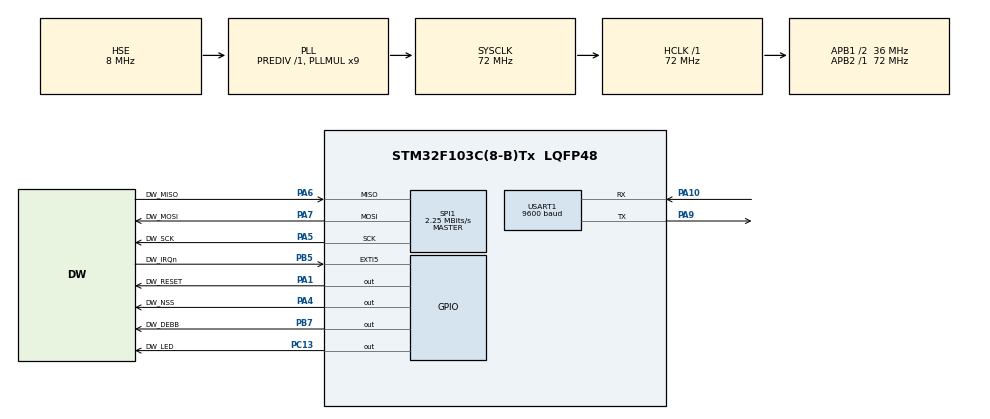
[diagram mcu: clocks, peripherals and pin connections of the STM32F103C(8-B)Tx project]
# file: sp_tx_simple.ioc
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Mcu.Family=STM32F1
Mcu.Name=STM32F103C(8-B)Tx
Mcu.Package=LQFP48
NVIC.EXTI9_5_IRQn=true\:1\:0\:true\:true\:true\:1\:true
NVIC.PriorityGroup=NVIC_PRIORITYGROUP_4
NVIC.TIM2_IRQn=true\:2\:0\:true\:true\:true\:2\:true
NVIC.TIM3_IRQn=true\:3\:0\:true\:true\:true\:3\:true
PA1.GPIO_Label=DW_RESET
PA1.GPIO_ModeDefaultOutputPP=GPIO_MODE_OUTPUT_OD
PA1.GPIO_Speed=GPIO_SPEED_FREQ_HIGH
PA1.PinState=GPIO_PIN_SET
PA1.Signal=GPIO_Output
PA10.Mode=Asynchronous
PA10.Signal=USART1_RX
PA13.Mode=Serial_Wire
PA13.Signal=SYS_JTMS-SWDIO
PA14.Mode=Serial_Wire
PA14.Signal=SYS_JTCK-SWCLK
PA4.GPIO_Label=DW_NSS
PA4.GPIO_Speed=GPIO_SPEED_FREQ_HIGH
PA4.PinState=GPIO_PIN_SET
PA4.Signal=GPIO_Output
PA5.GPIO_Label=DW_SCK
PA5.Mode=Full_Duplex_Master
PA5.Signal=SPI1_SCK
PA6.GPIO_Label=DW_MISO
PA6.Mode=Full_Duplex_Master
PA6.Signal=SPI1_MISO
PA7.GPIO_Label=DW_MOSI
PA7.Mode=Full_Duplex_Master
PA7.Signal=SPI1_MOSI
PA9.Mode=Asynchronous
PA9.Signal=USART1_TX
PB5.GPIO_Label=DW_IRQn
PB5.GPIO_PuPd=GPIO_PULLDOWN
PB5.Signal=GPXTI5
PB7.GPIO_Label=DW_DEBB
PB7.GPIO_Speed=GPIO_SPEED_FREQ_HIGH
PB7.PinState=GPIO_PIN_SET
PB7.Signal=GPIO_Output
PC13-TAMPER-RTC.GPIO_Label=DW_LED
PC13-TAMPER-RTC.GPIO_Speed=GPIO_SPEED_FREQ_HIGH
PC13-TAMPER-RTC.PinState=GPIO_PIN_SET
PC13-TAMPER-RTC.Signal=GPIO_Output
PC14-OSC32_IN.Mode=LSE-External-Oscillator
PC14-OSC32_IN.Signal=RCC_OSC32_IN
PC15-OSC32_OUT.Mode=LSE-External-Oscillator
PC15-OSC32_OUT.Signal=RCC_OSC32_OUT
PD0-OSC_IN.Mode=HSE-External-Oscillator
PD0-OSC_IN.Signal=RCC_OSC_IN
PD1-OSC_OUT.Mode=HSE-External-Oscillator
PD1-OSC_OUT.Signal=RCC_OSC_OUT
ProjectManager.HeapSize=0x1024
ProjectManager.StackSize=0x2048
ProjectManager.TargetToolchain=SW4STM32
RCC.AHBFreq_Value=72000000
RCC.APB1CLKDivider=RCC_HCLK_DIV2
RCC.APB1Freq_Value=36000000
RCC.APB1TimFreq_Value=72000000
RCC.APB2Freq_Value=72000000
RCC.APB2TimFreq_Value=72000000
RCC.HCLKFreq_Value=72000000
RCC.PLLMUL=RCC_PLL_MUL9
RCC.PLLSourceVirtual=RCC_PLLSOURCE_HSE
RCC.RCC_MCOSource=RCC_MCO1SOURCE_HSE
RCC.SYSCLKFreq_VALUE=72000000
RCC.SYSCLKSource=RCC_SYSCLKSOURCE_PLLCLK
RCC.USBFreq_Value=72000000
SPI1.BaudRatePrescaler=SPI_BAUDRATEPRESCALER_32
SPI1.CalculateBaudRate=2.25 MBits/s
SPI1.Direction=SPI_DIRECTION_2LINES
SPI1.Mode=SPI_MODE_MASTER
SPI1.VirtualType=VM_MASTER
TIM2.Period=14
TIM2.Prescaler=35999
TIM3.Period=1999
TIM3.Prescaler=35999
USART1.BaudRate=9600
USART1.VirtualMode=VM_ASYNC
VP_TIM2_VS_ClockSourceINT.Mode=Internal
VP_TIM3_VS_ClockSourceINT.Mode=Internal
board=sp_tx_simple

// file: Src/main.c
/**
  ******************************************************************************
  * File Name          : main.c
  * Description        : Main program body
  ******************************************************************************
  ** This notice applies to any and all portions of this file
  * that are not between comment pairs USER CODE BEGIN and
  * USER CODE END. Other portions of this file, whether
  * inserted by the user or by software development tools
  * are owned by their respective copyright owners.
  *
  * COPYRIGHT(c) 2018 STMicroelectronics
  *
  * Redistribution and use in source and binary forms, with or without modification,
  * are permitted provided that the following conditions are met:
  *   1. Redistributions of source code must retain the above copyright notice,
  *      this list of conditions and the following disclaimer.
  *   2. Redistributions in binary form must reproduce the above copyright notice,
  *      this list of conditions and the following disclaimer in the documentation
  *      and/or other materials provided with the distribution.
  *   3. Neither the name of STMicroelectronics nor the names of its contributors
  *      may be used to endorse or promote products derived from this software
  *      without specific prior written permission.
  *
  * THIS SOFTWARE IS PROVIDED BY THE COPYRIGHT HOLDERS AND CONTRIBUTORS "AS IS"
  * AND ANY EXPRESS OR IMPLIED WARRANTIES, INCLUDING, BUT NOT LIMITED TO, THE
  * IMPLIED WARRANTIES OF MERCHANTABILITY AND FITNESS FOR A PARTICULAR PURPOSE ARE
  * DISCLAIMED. IN NO EVENT SHALL THE COPYRIGHT HOLDER OR CONTRIBUTORS BE LIABLE
  * FOR ANY DIRECT, INDIRECT, INCIDENTAL, SPECIAL, EXEMPLARY, OR CONSEQUENTIAL
  * DAMAGES (INCLUDING, BUT NOT LIMITED TO, PROCUREMENT OF SUBSTITUTE GOODS OR
  * SERVICES; LOSS OF USE, DATA, OR PROFITS; OR BUSINESS INTERRUPTION) HOWEVER
  * CAUSED AND ON ANY THEORY OF LIABILITY, WHETHER IN CONTRACT, STRICT LIABILITY,
  * OR TORT (INCLUDING NEGLIGENCE OR OTHERWISE) ARISING IN ANY WAY OUT OF THE USE
  * OF THIS SOFTWARE, EVEN IF ADVISED OF THE POSSIBILITY OF SUCH DAMAGE.
  *
  ******************************************************************************
  */

#include "main.h"
#include "stm32f1xx_hal.h"

SPI_HandleTypeDef hspi1;

TIM_HandleTypeDef htim2;
TIM_HandleTypeDef htim3;

UART_HandleTypeDef huart1;

/* USER CODE BEGIN PV */
/* Private variables ---------------------------------------------------------*/

/* USER CODE END PV */

void SystemClock_Config(void);
static void MX_GPIO_Init(void);
static void MX_SPI1_Init(void);
static void MX_USART1_UART_Init(void);
static void MX_TIM2_Init(void);
static void MX_TIM3_Init(void);
static void MX_NVIC_Init(void);

/* USER CODE BEGIN PFP */
/* Private function prototypes -----------------------------------------------*/
extern void dw_main(void);
/* USER CODE END PFP */

/* USER CODE BEGIN 0 */
/*
#ifdef __GNUC__
#define PUTCHAR_PROTOTYPE int __io_putchar(int ch)
#else
#define PUTCHAR_PROTOTYPE int fputc(int ch, FILE *f)
#endif  __GNUC__
*/
/* USER CODE END 0 */

int main(void)
{

  /* MCU Configuration----------------------------------------------------------*/

  /* Reset of all peripherals, Initializes the Flash interface and the Systick. */
  HAL_Init();

  /* Configure the system clock */
  SystemClock_Config();

  /* Initialize all configured peripherals */
  MX_GPIO_Init();
  MX_SPI1_Init();
  MX_USART1_UART_Init();
  MX_TIM2_Init();
  MX_TIM3_Init();

  /* Initialize interrupts */
  MX_NVIC_Init();

  /* USER CODE BEGIN 2 */

/*  pitos = __HAL_RCC_TIM2_IS_CLK_ENABLED();
  if (pitos)
	  __HAL_RCC_TIM2_CLK_DISABLE();
  pitos = __HAL_RCC_TIM2_IS_CLK_ENABLED();*/

  __HAL_DBGMCU_FREEZE_TIM2();
  __HAL_DBGMCU_FREEZE_TIM3();

  dw_main();
  /* USER CODE END 2 */

  /* Infinite loop */
  while (1)
  {

  }

}

/** System Clock Configuration
*/
void SystemClock_Config(void)
{

  RCC_OscInitTypeDef RCC_OscInitStruct;
  RCC_ClkInitTypeDef RCC_ClkInitStruct;

    /**Initializes the CPU, AHB and APB busses clocks
    */
  RCC_OscInitStruct.OscillatorType = RCC_OSCILLATORTYPE_HSE;
  RCC_OscInitStruct.HSEState = RCC_HSE_ON;
  RCC_OscInitStruct.HSEPredivValue = RCC_HSE_PREDIV_DIV1;
  RCC_OscInitStruct.HSIState = RCC_HSI_ON;
  RCC_OscInitStruct.PLL.PLLState = RCC_PLL_ON;
  RCC_OscInitStruct.PLL.PLLSource = RCC_PLLSOURCE_HSE;
  RCC_OscInitStruct.PLL.PLLMUL = RCC_PLL_MUL9;
  if (HAL_RCC_OscConfig(&RCC_OscInitStruct) != HAL_OK)
  {
    _Error_Handler(__FILE__, __LINE__);
  }

    /**Initializes the CPU, AHB and APB busses clocks
    */
  RCC_ClkInitStruct.ClockType = RCC_CLOCKTYPE_HCLK|RCC_CLOCKTYPE_SYSCLK
                              |RCC_CLOCKTYPE_PCLK1|RCC_CLOCKTYPE_PCLK2;
  RCC_ClkInitStruct.SYSCLKSource = RCC_SYSCLKSOURCE_PLLCLK;
  RCC_ClkInitStruct.AHBCLKDivider = RCC_SYSCLK_DIV1;
  RCC_ClkInitStruct.APB1CLKDivider = RCC_HCLK_DIV2;
  RCC_ClkInitStruct.APB2CLKDivider = RCC_HCLK_DIV1;

  if (HAL_RCC_ClockConfig(&RCC_ClkInitStruct, FLASH_LATENCY_2) != HAL_OK)
  {
    _Error_Handler(__FILE__, __LINE__);
  }

    /**Configure the Systick interrupt time
    */
  HAL_SYSTICK_Config(HAL_RCC_GetHCLKFreq()/1000);

    /**Configure the Systick
    */
  HAL_SYSTICK_CLKSourceConfig(SYSTICK_CLKSOURCE_HCLK);

  /* SysTick_IRQn interrupt configuration */
  HAL_NVIC_SetPriority(SysTick_IRQn, 2, 0);
}

/** NVIC Configuration
*/
static void MX_NVIC_Init(void)
{
  /* EXTI9_5_IRQn interrupt configuration */
  HAL_NVIC_SetPriority(EXTI9_5_IRQn, 1, 0);
  HAL_NVIC_EnableIRQ(EXTI9_5_IRQn);
  /* TIM2_IRQn interrupt configuration */
  HAL_NVIC_SetPriority(TIM2_IRQn, 2, 0);
  HAL_NVIC_EnableIRQ(TIM2_IRQn);
  /* TIM3_IRQn interrupt configuration */
  HAL_NVIC_SetPriority(TIM3_IRQn, 3, 0);
  HAL_NVIC_EnableIRQ(TIM3_IRQn);
}

/* SPI1 init function */
static void MX_SPI1_Init(void)
{

  /* SPI1 parameter configuration*/
  hspi1.Instance = SPI1;
  hspi1.Init.Mode = SPI_MODE_MASTER;
  hspi1.Init.Direction = SPI_DIRECTION_2LINES;
  hspi1.Init.DataSize = SPI_DATASIZE_8BIT;
  hspi1.Init.CLKPolarity = SPI_POLARITY_LOW;
  hspi1.Init.CLKPhase = SPI_PHASE_1EDGE;
  hspi1.Init.NSS = SPI_NSS_SOFT;
  hspi1.Init.BaudRatePrescaler = SPI_BAUDRATEPRESCALER_32;
  hspi1.Init.FirstBit = SPI_FIRSTBIT_MSB;
  hspi1.Init.TIMode = SPI_TIMODE_DISABLE;
  hspi1.Init.CRCCalculation = SPI_CRCCALCULATION_DISABLE;
  hspi1.Init.CRCPolynomial = 10;
  if (HAL_SPI_Init(&hspi1) != HAL_OK)
  {
    _Error_Handler(__FILE__, __LINE__);
  }

}

/* TIM2 init function */
static void MX_TIM2_Init(void)
{

  TIM_ClockConfigTypeDef sClockSourceConfig;
  TIM_MasterConfigTypeDef sMasterConfig;

  htim2.Instance = TIM2;
  htim2.Init.Prescaler = 35999;
  htim2.Init.CounterMode = TIM_COUNTERMODE_UP;
  htim2.Init.Period = 14;
  htim2.Init.ClockDivision = TIM_CLOCKDIVISION_DIV1;
  htim2.Init.AutoReloadPreload = TIM_AUTORELOAD_PRELOAD_DISABLE;
  if (HAL_TIM_Base_Init(&htim2) != HAL_OK)
  {
    _Error_Handler(__FILE__, __LINE__);
  }

  sClockSourceConfig.ClockSource = TIM_CLOCKSOURCE_INTERNAL;
  if (HAL_TIM_ConfigClockSource(&htim2, &sClockSourceConfig) != HAL_OK)
  {
    _Error_Handler(__FILE__, __LINE__);
  }

  sMasterConfig.MasterOutputTrigger = TIM_TRGO_RESET;
  sMasterConfig.MasterSlaveMode = TIM_MASTERSLAVEMODE_DISABLE;
  if (HAL_TIMEx_MasterConfigSynchronization(&htim2, &sMasterConfig) != HAL_OK)
  {
    _Error_Handler(__FILE__, __LINE__);
  }

}

/* TIM3 init function */
static void MX_TIM3_Init(void)
{

  TIM_ClockConfigTypeDef sClockSourceConfig;
  TIM_MasterConfigTypeDef sMasterConfig;

  htim3.Instance = TIM3;
  htim3.Init.Prescaler = 35999;
  htim3.Init.CounterMode = TIM_COUNTERMODE_UP;
  htim3.Init.Period = 1999;
  htim3.Init.ClockDivision = TIM_CLOCKDIVISION_DIV1;
  htim3.Init.AutoReloadPreload = TIM_AUTORELOAD_PRELOAD_DISABLE;
  if (HAL_TIM_Base_Init(&htim3) != HAL_OK)
  {
    _Error_Handler(__FILE__, __LINE__);
  }

  sClockSourceConfig.ClockSource = TIM_CLOCKSOURCE_INTERNAL;
  if (HAL_TIM_ConfigClockSource(&htim3, &sClockSourceConfig) != HAL_OK)
  {
    _Error_Handler(__FILE__, __LINE__);
  }

  sMasterConfig.MasterOutputTrigger = TIM_TRGO_RESET;
  sMasterConfig.MasterSlaveMode = TIM_MASTERSLAVEMODE_DISABLE;
  if (HAL_TIMEx_MasterConfigSynchronization(&htim3, &sMasterConfig) != HAL_OK)
  {
    _Error_Handler(__FILE__, __LINE__);
  }

}

/* USART1 init function */
static void MX_USART1_UART_Init(void)
{

  huart1.Instance = USART1;
  huart1.Init.BaudRate = 9600;
  huart1.Init.WordLength = UART_WORDLENGTH_8B;
  huart1.Init.StopBits = UART_STOPBITS_1;
  huart1.Init.Parity = UART_PARITY_NONE;
  huart1.Init.Mode = UART_MODE_TX_RX;
  huart1.Init.HwFlowCtl = UART_HWCONTROL_NONE;
  huart1.Init.OverSampling = UART_OVERSAMPLING_16;
  if (HAL_UART_Init(&huart1) != HAL_OK)
  {
    _Error_Handler(__FILE__, __LINE__);
  }

}

/** Configure pins as
        * Analog
        * Input
        * Output
        * EVENT_OUT
        * EXTI
*/
static void MX_GPIO_Init(void)
{

  GPIO_InitTypeDef GPIO_InitStruct;

  /* GPIO Ports Clock Enable */
  __HAL_RCC_GPIOC_CLK_ENABLE();
  __HAL_RCC_GPIOD_CLK_ENABLE();
  __HAL_RCC_GPIOA_CLK_ENABLE();
  __HAL_RCC_GPIOB_CLK_ENABLE();

  /*Configure GPIO pin Output Level */
  HAL_GPIO_WritePin(DW_LED_GPIO_Port, DW_LED_Pin, GPIO_PIN_SET);

  /*Configure GPIO pin Output Level */
  HAL_GPIO_WritePin(GPIOA, DW_RESET_Pin|DW_NSS_Pin, GPIO_PIN_SET);

  /*Configure GPIO pin Output Level */
  HAL_GPIO_WritePin(DW_DEBB_GPIO_Port, DW_DEBB_Pin, GPIO_PIN_SET);

  /*Configure GPIO pin : DW_LED_Pin */
  GPIO_InitStruct.Pin = DW_LED_Pin;
  GPIO_InitStruct.Mode = GPIO_MODE_OUTPUT_PP;
  GPIO_InitStruct.Speed = GPIO_SPEED_FREQ_HIGH;
  HAL_GPIO_Init(DW_LED_GPIO_Port, &GPIO_InitStruct);

  /*Configure GPIO pin : DW_RESET_Pin */
  GPIO_InitStruct.Pin = DW_RESET_Pin;
  GPIO_InitStruct.Mode = GPIO_MODE_OUTPUT_OD;
  GPIO_InitStruct.Speed = GPIO_SPEED_FREQ_HIGH;
  HAL_GPIO_Init(DW_RESET_GPIO_Port, &GPIO_InitStruct);

  /*Configure GPIO pin : DW_NSS_Pin */
  GPIO_InitStruct.Pin = DW_NSS_Pin;
  GPIO_InitStruct.Mode = GPIO_MODE_OUTPUT_PP;
  GPIO_InitStruct.Speed = GPIO_SPEED_FREQ_HIGH;
  HAL_GPIO_Init(DW_NSS_GPIO_Port, &GPIO_InitStruct);

  /*Configure GPIO pin : DW_IRQn_Pin */
  GPIO_InitStruct.Pin = DW_IRQn_Pin;
  GPIO_InitStruct.Mode = GPIO_MODE_IT_RISING;
  GPIO_InitStruct.Pull = GPIO_PULLDOWN;
  HAL_GPIO_Init(DW_IRQn_GPIO_Port, &GPIO_InitStruct);

  /*Configure GPIO pin : DW_DEBB_Pin */
  GPIO_InitStruct.Pin = DW_DEBB_Pin;
  GPIO_InitStruct.Mode = GPIO_MODE_OUTPUT_PP;
  GPIO_InitStruct.Speed = GPIO_SPEED_FREQ_HIGH;
  HAL_GPIO_Init(DW_DEBB_GPIO_Port, &GPIO_InitStruct);

}

/* USER CODE BEGIN 4 */

void Error_Led(int cuantos)
{
	return;
	  for(int i=0; i<cuantos; i++)
	  {
		  HAL_Delay(100);
		  HAL_GPIO_TogglePin(DW_LED_GPIO_Port, DW_LED_Pin);
	  }
}

/* USER CODE END 4 */

void _Error_Handler(char * file, int line)
{
  /* USER CODE BEGIN Error_Handler_Debug */
  /* User can add his own implementation to report the HAL error return state */
	while(1)
	  {
		  HAL_Delay(100);
		  HAL_GPIO_TogglePin(DW_LED_GPIO_Port, DW_LED_Pin);
	  }
  /* USER CODE END Error_Handler_Debug */
}

/************************ (C) COPYRIGHT STMicroelectronics *****END OF FILE****/
